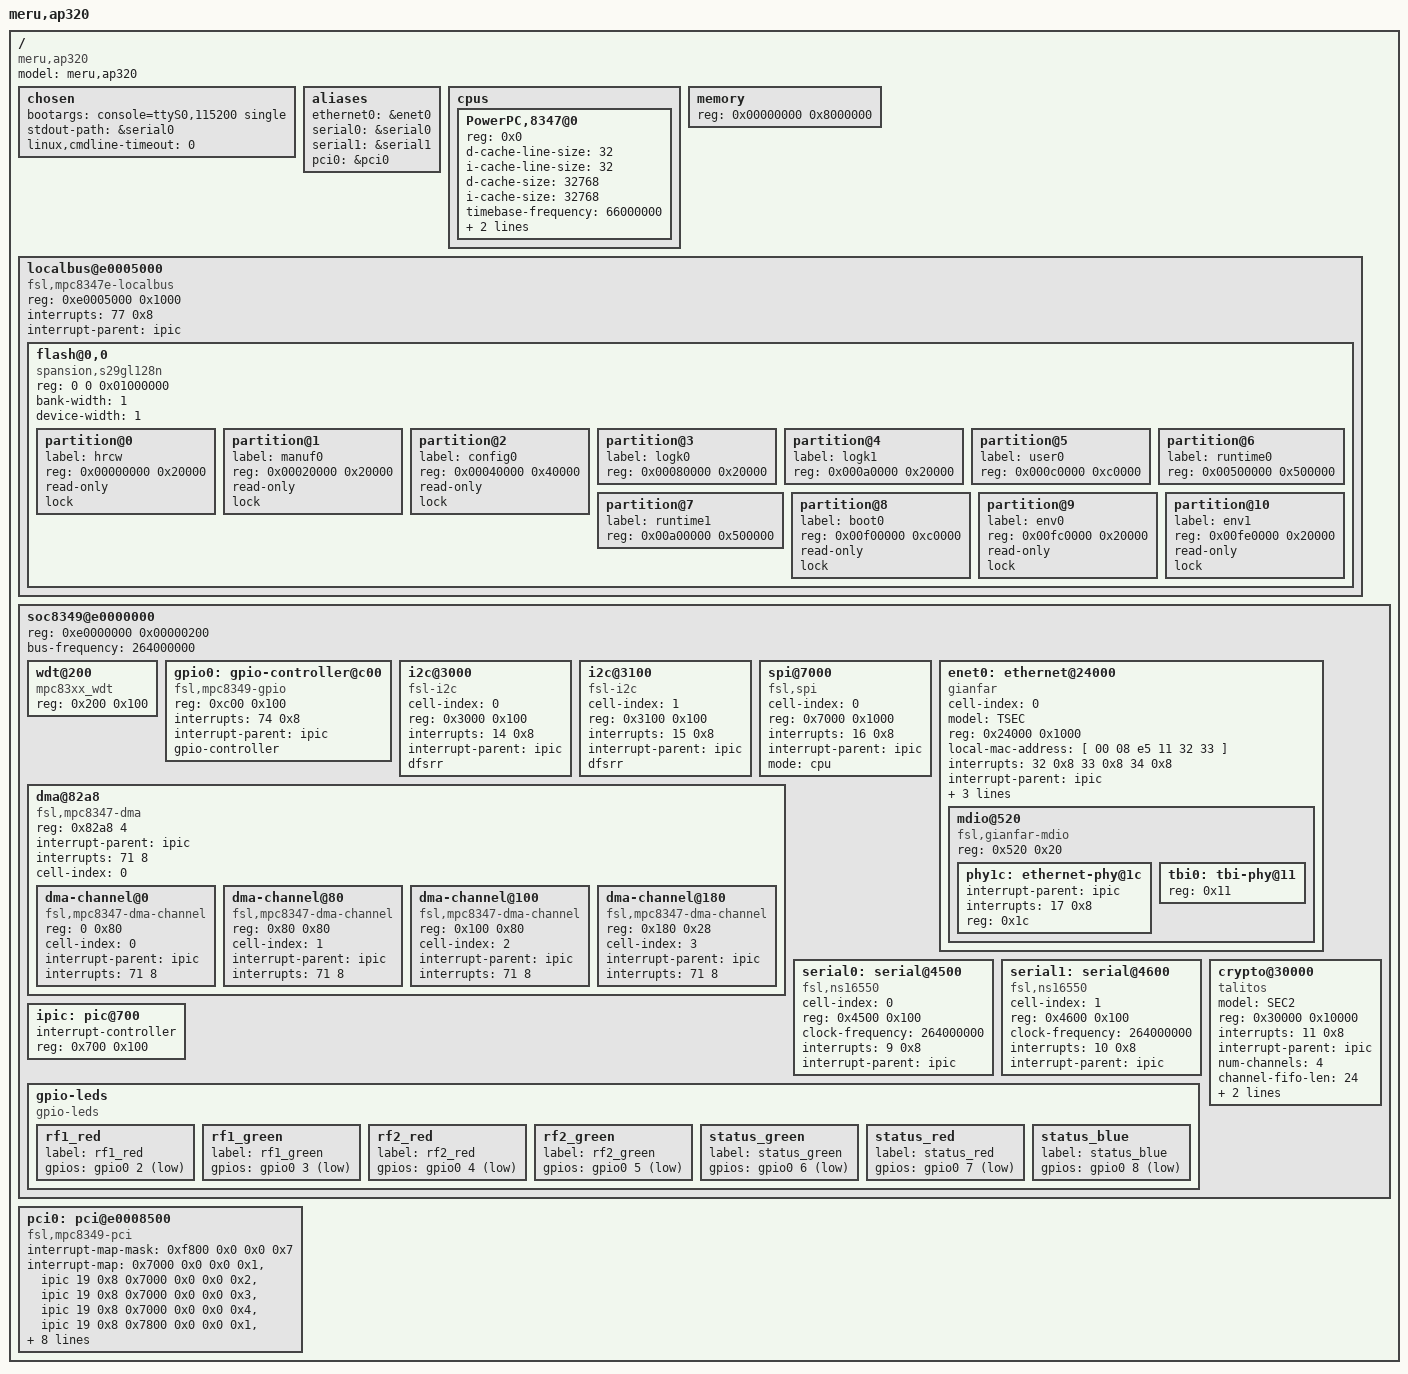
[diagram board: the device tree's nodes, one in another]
// SPDX-License-Identifier: GPL-2.0-or-later
/*
 * Meru Networks AP320 Device Tree Source
 *
 * Copyright 2020 Celliwig
 */

/dts-v1/;

#include <dt-bindings/gpio/gpio.h>

/ {
	model = "meru,ap320";
	compatible = "meru,ap320", "meru,mpc8347";
	#address-cells = <1>;
	#size-cells = <1>;

	chosen {
//		bootargs = "console=ttyS0,38400 root=/dev/mtdblock3 rootfstype=jffs2";
		bootargs = "console=ttyS0,115200 single";
		stdout-path = &serial0;
		linux,cmdline-timeout=<0>;
	};

	aliases {
		ethernet0 = &enet0;
//		ethernet1 = &enet1;
		serial0 = &serial0;
		serial1 = &serial1;
		pci0 = &pci0;
//		pci1 = &pci1;
	};

	cpus {
		#address-cells = <1>;
		#size-cells = <0>;

		PowerPC,8347@0 {
			device_type = "cpu";
			reg = <0x0>;
			d-cache-line-size = <32>;
			i-cache-line-size = <32>;
			d-cache-size = <32768>;
			i-cache-size = <32768>;
			timebase-frequency = <66000000>;	// Should be from bootloader
			bus-frequency = <264000000>;		// Should be from bootloader
			clock-frequency = <528000000>;		// Should be from bootloader
//			timebase-frequency = <0>;	// Should be from bootloader
//			bus-frequency = <0>;		// Should be from bootloader
//			clock-frequency = <0>;		// Should be from bootloader
		};
	};

	memory {
		device_type = "memory";
		reg = <0x00000000 0x8000000>;	// 128MB at 0
	};

//	localbus@ff005000 {
	localbus@e0005000 {
		#address-cells = <2>;
		#size-cells = <1>;
		compatible = "fsl,mpc8347e-localbus",
			     "fsl,pq2pro-localbus",
			     "simple-bus";
//		reg = <0xff005000 0x1000>;
		reg = <0xe0005000 0x1000>;
		interrupts = <77 0x8>;
		interrupt-parent = <&ipic>;

		ranges = <
			0 0 0xff000000 0x01000000
		>;

		flash@0,0 {
			compatible = "spansion,s29gl128n", "cfi-flash";
			reg = <0 0 0x01000000>;
			bank-width = <1>;
			device-width = <1>;
			#address-cells = <1>;
			#size-cells = <1>;

			// 0x00000000-0x00020000 (hrcw)
			partition@0 {
				label = "hrcw";
				reg = <0x00000000 0x20000>;		// 128k
				read-only;
				lock;
			};
			// 0x00020000-0x00040000 (manuf0)
			partition@1 {
				label = "manuf0";
				reg = <0x00020000 0x20000>;		// 128k
				read-only;
				lock;
			};
			// 0x00040000-0x00080000 (config0)
			partition@2 {
				label = "config0";
				reg = <0x00040000 0x40000>;		// 256k
				read-only;
				lock;
			};
			// 0x00080000-0x000a0000 (logk0)
			partition@3 {
				label = "logk0";
				reg = <0x00080000 0x20000>;		// 128k
			};
			// 0x000a0000-0x000c0000 (logk1)
			partition@4 {
				label = "logk1";
				reg = <0x000a0000 0x20000>;		// 128k
			};
			// 0x000c0000-0x00180000 (user0)
			partition@5 {
				label = "user0";
				reg = <0x000c0000 0xc0000>;		// 768k
			};
			// 0x00500000-0x00a00000 (runtime0)
			partition@6 {
				label = "runtime0";
				reg = <0x00500000 0x500000>;		// 5M
			};
			// 0x00a00000-0x00f00000 (runtime1)
			partition@7 {
				label = "runtime1";
				reg = <0x00a00000 0x500000>;		// 5M
			};
			// 0x00f00000-0x00fc0000 (boot0)
			partition@8 {
				label = "boot0";
				reg = <0x00f00000 0xc0000>;		// 768k
				read-only;
				lock;
			};
			// 0x00fc0000-0x00fe0000 (env0)
			partition@9 {
				label = "env0";
				reg = <0x00fc0000 0x20000>;		// 128k
				read-only;
				lock;
			};
			// 0x00fe0000-0x01000000 (env1)
			partition@10 {
				label = "env1";
				reg = <0x00fe0000 0x20000>;		// 128k
				read-only;
				lock;
			};
		};
	};

//	soc8349@ff000000 {
	soc8349@e0000000 {
		#address-cells = <1>;
		#size-cells = <1>;
		device_type = "soc";
//		ranges = <0x0 0xff000000 0x00100000>;
//		reg = <0xff000000 0x00000200>;
		ranges = <0x0 0xe0000000 0x00100000>;
		reg = <0xe0000000 0x00000200>;
		bus-frequency = <264000000>;
//		bus-frequency = <0>;

		wdt@200 {
			device_type = "watchdog";
			compatible = "mpc83xx_wdt";
			reg = <0x200 0x100>;
		};

		gpio0: gpio-controller@c00 {
			#gpio-cells = <2>;
			compatible = "fsl,mpc8349-gpio";
			reg = <0xc00 0x100>;
			interrupts = <74 0x8>;
			interrupt-parent = <&ipic>;
			gpio-controller;
		};

//		gpio1: gpio-controller@d00 {
//			#gpio-cells = <2>;
//			compatible = "fsl,mpc8349-gpio";
//			reg = <0xd00 0x100>;
//			interrupts = <75 0x8>;
//			interrupt-parent = <&ipic>;
//			gpio-controller;
//		};

		i2c@3000 {
			#address-cells = <1>;
			#size-cells = <0>;
			cell-index = <0>;
			compatible = "fsl-i2c";
			reg = <0x3000 0x100>;
			interrupts = <14 0x8>;
			interrupt-parent = <&ipic>;
			dfsrr;

//			rtc@68 {
//				compatible = "dallas,ds1374";
//				reg = <0x68>;
//			};
		};

		i2c@3100 {
			#address-cells = <1>;
			#size-cells = <0>;
			cell-index = <1>;
			compatible = "fsl-i2c";
			reg = <0x3100 0x100>;
			interrupts = <15 0x8>;
			interrupt-parent = <&ipic>;
			dfsrr;
		};

		spi@7000 {
			cell-index = <0>;
			compatible = "fsl,spi";
			reg = <0x7000 0x1000>;
			interrupts = <16 0x8>;
			interrupt-parent = <&ipic>;
			mode = "cpu";
		};

		dma@82a8 {
			#address-cells = <1>;
			#size-cells = <1>;
			compatible = "fsl,mpc8347-dma", "fsl,elo-dma";
			reg = <0x82a8 4>;
			ranges = <0 0x8100 0x1a8>;
			interrupt-parent = <&ipic>;
			interrupts = <71 8>;
			cell-index = <0>;
			dma-channel@0 {
				compatible = "fsl,mpc8347-dma-channel", "fsl,elo-dma-channel";
				reg = <0 0x80>;
				cell-index = <0>;
				interrupt-parent = <&ipic>;
				interrupts = <71 8>;
			};
			dma-channel@80 {
				compatible = "fsl,mpc8347-dma-channel", "fsl,elo-dma-channel";
				reg = <0x80 0x80>;
				cell-index = <1>;
				interrupt-parent = <&ipic>;
				interrupts = <71 8>;
			};
			dma-channel@100 {
				compatible = "fsl,mpc8347-dma-channel", "fsl,elo-dma-channel";
				reg = <0x100 0x80>;
				cell-index = <2>;
				interrupt-parent = <&ipic>;
				interrupts = <71 8>;
			};
			dma-channel@180 {
				compatible = "fsl,mpc8347-dma-channel", "fsl,elo-dma-channel";
				reg = <0x180 0x28>;
				cell-index = <3>;
				interrupt-parent = <&ipic>;
				interrupts = <71 8>;
			};
		};

//		/* phy type (ULPI or SERIAL) are only types supported for MPH */
//		/* port = 0 or 1 */
//		usb@22000 {
//			compatible = "fsl-usb2-mph";
//			reg = <0x22000 0x1000>;
//			#address-cells = <1>;
//			#size-cells = <0>;
//			interrupt-parent = <&ipic>;
//			interrupts = <39 0x8>;
//			phy_type = "ulpi";
//			port0;
//		};
//		/* phy type (ULPI, UTMI, UTMI_WIDE, SERIAL) */
//		usb@23000 {
//			compatible = "fsl-usb2-dr";
//			reg = <0x23000 0x1000>;
//			#address-cells = <1>;
//			#size-cells = <0>;
//			interrupt-parent = <&ipic>;
//			interrupts = <38 0x8>;
//			dr_mode = "otg";
//			phy_type = "ulpi";
//		};

		enet0: ethernet@24000 {
			#address-cells = <1>;
			#size-cells = <1>;
			cell-index = <0>;
			device_type = "network";
			model = "TSEC";
			compatible = "gianfar";
			reg = <0x24000 0x1000>;
			ranges = <0x0 0x24000 0x1000>;
			local-mac-address = [ 00 08 e5 11 32 33 ];
			interrupts = <32 0x8 33 0x8 34 0x8>;
			interrupt-parent = <&ipic>;
			tbi-handle = <&tbi0>;
			phy-handle = <&phy1c>;
			linux,network-index = <0>;

			mdio@520 {
				#address-cells = <1>;
				#size-cells = <0>;
				compatible = "fsl,gianfar-mdio";
				reg = <0x520 0x20>;

				/* Vitesse 8601 */
				phy1c: ethernet-phy@1c {
					interrupt-parent = <&ipic>;
					interrupts = <17 0x8>;
					reg = <0x1c>;
				};

				tbi0: tbi-phy@11 {
					reg = <0x11>;
					device_type = "tbi-phy";
				};
			};
		};

//		enet1: ethernet@25000 {
//			#address-cells = <1>;
//			#size-cells = <1>;
//			cell-index = <1>;
//			device_type = "network";
//			model = "TSEC";
//			compatible = "gianfar";
//			reg = <0x25000 0x1000>;
//			ranges = <0x0 0x25000 0x1000>;
//			local-mac-address = [ 00 08 e5 11 32 34 ];
//			interrupts = <35 0x8 36 0x8 37 0x8>;
//			interrupt-parent = <&ipic>;
//			tbi-handle = <&tbi1>;
//			phy-handle = <&phy1>;
//			linux,network-index = <1>;
//
//			mdio@520 {
//				#address-cells = <1>;
//				#size-cells = <0>;
//				compatible = "fsl,gianfar-tbi";
//				reg = <0x520 0x20>;
//
//				tbi1: tbi-phy@11 {
//					reg = <0x11>;
//					device_type = "tbi-phy";
//				};
//			};
//		};

		serial0: serial@4500 {
			cell-index = <0>;
			device_type = "serial";
			compatible = "fsl,ns16550", "ns16550";
			reg = <0x4500 0x100>;
			clock-frequency = <264000000>;
			interrupts = <9 0x8>;
			interrupt-parent = <&ipic>;
		};

		serial1: serial@4600 {
			cell-index = <1>;
			device_type = "serial";
			compatible = "fsl,ns16550", "ns16550";
			reg = <0x4600 0x100>;
			clock-frequency = <264000000>;
			interrupts = <10 0x8>;
			interrupt-parent = <&ipic>;
		};

		/* May need to remove if on a part without crypto engine */
		crypto@30000 {
			device_type = "crypto";
			model = "SEC2";
			compatible = "talitos";
			reg = <0x30000 0x10000>;
			interrupts = <11 0x8>;
			interrupt-parent = <&ipic>;
			num-channels = <4>;
			channel-fifo-len = <24>;
			exec-units-mask = <0x0000007e>;
			/* desc mask is for rev2.0,
			 * we need runtime fixup for >2.0 */
			descriptor-types-mask = <0x01010ebf>;
		};

		/* IPIC
		 * interrupts cell = <intr #, sense>
		 * sense values match linux IORESOURCE_IRQ_* defines:
		 * sense == 8: Level, low assertion
		 * sense == 2: Edge, high-to-low change
		 */
		ipic: pic@700 {
			interrupt-controller;
			#address-cells = <0>;
			#interrupt-cells = <2>;
			reg = <0x700 0x100>;
			device_type = "ipic";
		};

		gpio-leds {
			compatible = "gpio-leds";

			// RF1
			rf1_red {
				label = "rf1_red";
				gpios = <&gpio0 2 GPIO_ACTIVE_LOW>;
			};
			rf1_green {
				label = "rf1_green";
				gpios = <&gpio0 3 GPIO_ACTIVE_LOW>;
			};

			// RF2
			rf2_red {
				label = "rf2_red";
				gpios = <&gpio0 4 GPIO_ACTIVE_LOW>;
			};
			rf2_green {
				label = "rf2_green";
				gpios = <&gpio0 5 GPIO_ACTIVE_LOW>;
			};

			// Status
			status_green {
				label = "status_green";
				gpios = <&gpio0 6 GPIO_ACTIVE_LOW>;
			};
			status_red {
				label = "status_red";
				gpios = <&gpio0 7 GPIO_ACTIVE_LOW>;
			};
			status_blue {
				label = "status_blue";
				gpios = <&gpio0 8 GPIO_ACTIVE_LOW>;
			};
		};
	};

	pci0: pci@e0008500 {
		interrupt-map-mask = <0xf800 0x0 0x0 0x7>;
		interrupt-map = <
				/* IDSEL 0x0E -mini PCI */
				 0x7000 0x0 0x0 0x1 &ipic 19 0x8
				 0x7000 0x0 0x0 0x2 &ipic 19 0x8
				 0x7000 0x0 0x0 0x3 &ipic 19 0x8
				 0x7000 0x0 0x0 0x4 &ipic 19 0x8

				/* IDSEL 0x0F - PCI slot */
				 0x7800 0x0 0x0 0x1 &ipic 20 0x8
				 0x7800 0x0 0x0 0x2 &ipic 20 0x8
				 0x7800 0x0 0x0 0x3 &ipic 20 0x8
				 0x7800 0x0 0x0 0x4 &ipic 20 0x8>;
		interrupt-parent = <&ipic>;
		interrupts = <66 0x8>;
		bus-range = <0x0 0x0>;
		ranges = <0x02000000 0x0 0x90000000 0x90000000 0x0 0x10000000
			  0x42000000 0x0 0x80000000 0x80000000 0x0 0x10000000
			  0x01000000 0x0 0x00000000 0xe2000000 0x0 0x00100000>;
		clock-frequency = <66666666>;
		#interrupt-cells = <1>;
		#size-cells = <2>;
		#address-cells = <3>;
		reg = <0xe0008500 0x100		/* internal registers */
		       0xe0008300 0x8>;		/* config space access registers */
		compatible = "fsl,mpc8349-pci";
		device_type = "pci";
	};

//	pci0: pci@e0008500 {
//		interrupt-map-mask = <0xf800 0x0 0x0 0x7>;
//		interrupt-map = <
//
//				/* IDSEL 0x11 */
//				 0x8800 0x0 0x0 0x1 &ipic 20 0x8
//				 0x8800 0x0 0x0 0x2 &ipic 21 0x8
//				 0x8800 0x0 0x0 0x3 &ipic 22 0x8
//				 0x8800 0x0 0x0 0x4 &ipic 23 0x8
//
//				/* IDSEL 0x12 */
//				 0x9000 0x0 0x0 0x1 &ipic 22 0x8
//				 0x9000 0x0 0x0 0x2 &ipic 23 0x8
//				 0x9000 0x0 0x0 0x3 &ipic 20 0x8
//				 0x9000 0x0 0x0 0x4 &ipic 21 0x8
//
//				/* IDSEL 0x13 */
//				 0x9800 0x0 0x0 0x1 &ipic 23 0x8
//				 0x9800 0x0 0x0 0x2 &ipic 20 0x8
//				 0x9800 0x0 0x0 0x3 &ipic 21 0x8
//				 0x9800 0x0 0x0 0x4 &ipic 22 0x8
//
//				/* IDSEL 0x15 */
//				 0xa800 0x0 0x0 0x1 &ipic 20 0x8
//				 0xa800 0x0 0x0 0x2 &ipic 21 0x8
//				 0xa800 0x0 0x0 0x3 &ipic 22 0x8
//				 0xa800 0x0 0x0 0x4 &ipic 23 0x8
//
//				/* IDSEL 0x16 */
//				 0xb000 0x0 0x0 0x1 &ipic 23 0x8
//				 0xb000 0x0 0x0 0x2 &ipic 20 0x8
//				 0xb000 0x0 0x0 0x3 &ipic 21 0x8
//				 0xb000 0x0 0x0 0x4 &ipic 22 0x8
//
//				/* IDSEL 0x17 */
//				 0xb800 0x0 0x0 0x1 &ipic 22 0x8
//				 0xb800 0x0 0x0 0x2 &ipic 23 0x8
//				 0xb800 0x0 0x0 0x3 &ipic 20 0x8
//				 0xb800 0x0 0x0 0x4 &ipic 21 0x8
//
//				/* IDSEL 0x18 */
//				 0xc000 0x0 0x0 0x1 &ipic 21 0x8
//				 0xc000 0x0 0x0 0x2 &ipic 22 0x8
//				 0xc000 0x0 0x0 0x3 &ipic 23 0x8
//				 0xc000 0x0 0x0 0x4 &ipic 20 0x8>;
//		interrupt-parent = <&ipic>;
//		interrupts = <66 0x8>;
//		bus-range = <0 0>;
//		ranges = <0x02000000 0x0 0x90000000 0x90000000 0x0 0x10000000
//			  0x42000000 0x0 0x80000000 0x80000000 0x0 0x10000000
//			  0x01000000 0x0 0x00000000 0xe2000000 0x0 0x00100000>;
//		clock-frequency = <66666666>;
//		#interrupt-cells = <1>;
//		#size-cells = <2>;
//		#address-cells = <3>;
//		reg = <0xe0008500 0x100		/* internal registers */
//		       0xe0008300 0x8>;		/* config space access registers */
//		compatible = "fsl,mpc8349-pci";
//		device_type = "pci";
//	};

//	pci1: pci@e0008600 {
//		interrupt-map-mask = <0xf800 0x0 0x0 0x7>;
//		interrupt-map = <
//
//				/* IDSEL 0x11 */
//				 0x8800 0x0 0x0 0x1 &ipic 20 0x8
//				 0x8800 0x0 0x0 0x2 &ipic 21 0x8
//				 0x8800 0x0 0x0 0x3 &ipic 22 0x8
//				 0x8800 0x0 0x0 0x4 &ipic 23 0x8
//
//				/* IDSEL 0x12 */
//				 0x9000 0x0 0x0 0x1 &ipic 22 0x8
//				 0x9000 0x0 0x0 0x2 &ipic 23 0x8
//				 0x9000 0x0 0x0 0x3 &ipic 20 0x8
//				 0x9000 0x0 0x0 0x4 &ipic 21 0x8
//
//				/* IDSEL 0x13 */
//				 0x9800 0x0 0x0 0x1 &ipic 23 0x8
//				 0x9800 0x0 0x0 0x2 &ipic 20 0x8
//				 0x9800 0x0 0x0 0x3 &ipic 21 0x8
//				 0x9800 0x0 0x0 0x4 &ipic 22 0x8
//
//				/* IDSEL 0x15 */
//				 0xa800 0x0 0x0 0x1 &ipic 20 0x8
//				 0xa800 0x0 0x0 0x2 &ipic 21 0x8
//				 0xa800 0x0 0x0 0x3 &ipic 22 0x8
//				 0xa800 0x0 0x0 0x4 &ipic 23 0x8
//
//				/* IDSEL 0x16 */
//				 0xb000 0x0 0x0 0x1 &ipic 23 0x8
//				 0xb000 0x0 0x0 0x2 &ipic 20 0x8
//				 0xb000 0x0 0x0 0x3 &ipic 21 0x8
//				 0xb000 0x0 0x0 0x4 &ipic 22 0x8
//
//				/* IDSEL 0x17 */
//				 0xb800 0x0 0x0 0x1 &ipic 22 0x8
//				 0xb800 0x0 0x0 0x2 &ipic 23 0x8
//				 0xb800 0x0 0x0 0x3 &ipic 20 0x8
//				 0xb800 0x0 0x0 0x4 &ipic 21 0x8
//
//				/* IDSEL 0x18 */
//				 0xc000 0x0 0x0 0x1 &ipic 21 0x8
//				 0xc000 0x0 0x0 0x2 &ipic 22 0x8
//				 0xc000 0x0 0x0 0x3 &ipic 23 0x8
//				 0xc000 0x0 0x0 0x4 &ipic 20 0x8>;
//		interrupt-parent = <&ipic>;
//		interrupts = <67 0x8>;
//		bus-range = <0 0>;
//		ranges = <0x02000000 0x0 0xb0000000 0xb0000000 0x0 0x10000000
//			  0x42000000 0x0 0xa0000000 0xa0000000 0x0 0x10000000
//			  0x01000000 0x0 0x00000000 0xe2100000 0x0 0x00100000>;
//		clock-frequency = <66666666>;
//		#interrupt-cells = <1>;
//		#size-cells = <2>;
//		#address-cells = <3>;
//		reg = <0xe0008600 0x100		/* internal registers */
//		       0xe0008380 0x8>;		/* config space access registers */
//		compatible = "fsl,mpc8349-pci";
//		device_type = "pci";
//	};
};
